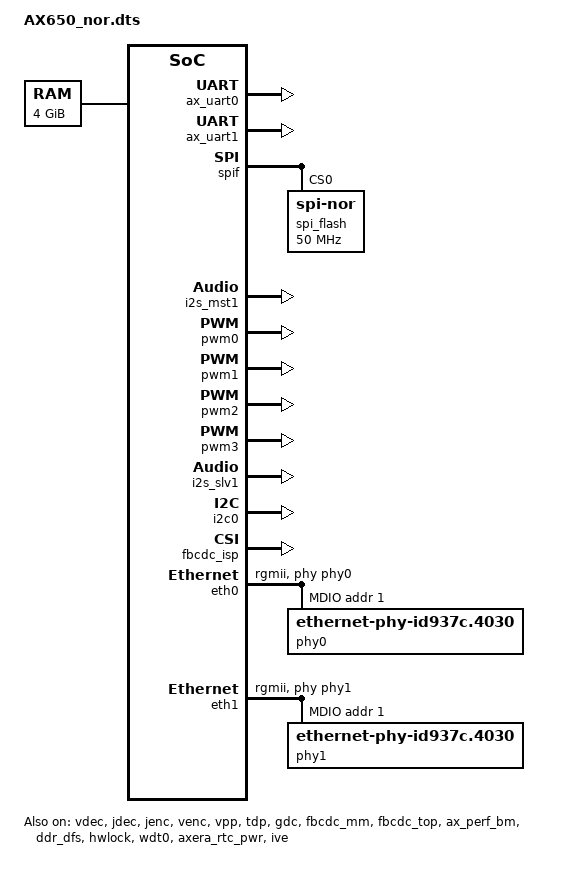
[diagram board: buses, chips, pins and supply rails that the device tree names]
// SPDX-License-Identifier: GPL-2.0
/*
 * dts file for Axera EVB Development Board
 *
 * Copyright (C) 2020, Axera Ltd.
 *
 */

/dts-v1/;
#include "AX650.dtsi"
#include "AX650_pinctrl.dtsi"
#include <dt-bindings/phy/jlsemi-dt-phy.h>
/ {
	memory@100000000 {
		device_type = "memory";
		reg = <0x1 0x00000000 0x1 0x00000000>;
	};
	reserved-memory {
		#address-cells = <2>;
		#size-cells = <2>;
		ranges;
		linux,cma {
			compatible = "shared-dma-pool";
			reusable;
			size = <0x00000000 0x2000000>;
			linux,cma-default;
		};
		axera_memory_dump@0 {
			compatible = "axera_memory_dump";
			reg = <0x1 0x050f0000 0x0 0x1000>;
			fix_addr = <0x7C8D6E02>;
		};
		ramoops_mem@106000000 {
			compatible = "ramoops";
			reg = <0x1 0x06000000 0x0 0xf0000>;
			record-size = <0x40000>;
			console-size = <0x80000>;
			ftrace-size = <0x20000>;
		};
	};

	chosen {
		bootargs = "Please DO NOT config this parameter. Please DO NOT config this parameter. Please DO NOT config this parameter. Please DO NOT config this parameter. Please DO NOT config this parameter. Please DO NOT config this parameter. Please DO NOT config this parameter. Please DO NOT config this parameter. Please config BOOTARGS_EMMC/BOOTARGS_SPINOR/BOOTARGS_SPI in u-boot-2020.04/include/configs/ax650_nor.h";
	};

	usb30: dwc3@0x30c00000 {
		compatible = "snps,dwc3";
		status = "okay";
	};

	usb31: dwc3@0x30d00000 {
		compatible = "snps,dwc3";
		status = "okay";
	};

	usb32: dwc3@0x28100000 {
		compatible = "snps,dwc3";
		status = "okay";
	};

	aliases {
		usb0 = &usb30;
		usb1 = &usb31;
		usb2 = &usb32;
	};

	fbcdc_config_val: fbcdc_config_val@0 {
		regs-num = <0x62>;
		regs-val = <0x00000020 0x00000001>,
			   <0x00000024 0x00000001>,
			   <0x00000000 0x00000000>,
			   <0x00000014 0x00000000>,
			   <0x00000048 0x0000001c>,
			   <0x0000024c 0x00000010>,
			   <0x0000004c 0x8000006b>,
			   <0x00000054 0x8000006b>,
			   <0x0000005c 0xc7b8a46b>,
			   <0x00000064 0xc7b8a46b>,
			   <0x0000006c 0x70000004>,
			   <0x00000074 0xc5040f71>,
			   <0x0000007c 0xc7148d60>,
			   <0x00000084 0x60000000>,
			   <0x0000008c 0x20000000>,
			   <0x00000094 0x50000000>,
			   <0x0000009c 0xc5a8207b>,
			   <0x000000a4 0x40000000>,
			   <0x000000ac 0xc7b8a46b>,
			   <0x000000b4 0x70000004>,
			   <0x000000bc 0xb0148d60>,
			   <0x000000c4 0x9000124a>,
			   <0x000000cc 0xb0148d60>,
			   <0x000000d4 0x9000124a>,
			   <0x000000dc 0xb0148d60>,
			   <0x000000e4 0x9000124a>,
			   <0x000000ec 0xb0148d60>,
			   <0x000000f4 0x9000124a>,
			   <0x000000fc 0xb0148d60>,
			   <0x00000104 0x9000124a>,
			   <0x0000010c 0xb0148d60>,
			   <0x00000114 0x9000124a>,
			   <0x0000011c 0xb0148d60>,
			   <0x00000124 0x9000124a>,
			   <0x0000012c 0x10000000>,
			   <0x00000050 0x0625a820>,
			   <0x00000058 0x0625a820>,
			   <0x00000060 0x0625a820>,
			   <0x00000068 0x0625a820>,
			   <0x00000070 0x0e65a820>,
			   <0x00000078 0x48d60c51>,
			   <0x00000080 0xc5181ccb>,
			   <0x00000088 0x10b5040f>,
			   <0x00000090 0x00000249>,
			   <0x00000098 0x01181cd3>,
			   <0x000000a0 0x8a46b062>,
			   <0x000000a8 0x0009c928>,
			   <0x000000b0 0x0628c0e6>,
			   <0x000000b8 0x9285a820>,
			   <0x000000c0 0xc5181cd3>,
			   <0x000000c8 0x16a081ee>,
			   <0x000000d0 0xc5181cd3>,
			   <0x000000d8 0x16a081ee>,
			   <0x000000e0 0xc5181cd3>,
			   <0x000000e8 0x16a081ee>,
			   <0x000000f0 0xc5181cd3>,
			   <0x000000f8 0x16a081ee>,
			   <0x00000100 0xc5181cd3>,
			   <0x00000108 0x16a081ee>,
			   <0x00000110 0xc5181cd3>,
			   <0x00000118 0x16a081ee>,
			   <0x00000120 0xc5181cd3>,
			   <0x00000128 0x16a081ee>,
			   <0x00000130 0x00000013>,
			   <0x00000250 0x40000000>,
			   <0x00000258 0x40000000>,
			   <0x00000260 0x60000000>,
			   <0x00000268 0x60000000>,
			   <0x00000270 0x80000029>,
			   <0x00000278 0x80000029>,
			   <0x00000280 0x30000000>,
			   <0x00000288 0x90000101>,
			   <0x00000290 0xa0002029>,
			   <0x00000298 0xa0002029>,
			   <0x000002a0 0xa0002029>,
			   <0x000002a8 0xa0002029>,
			   <0x000002b0 0xa0002029>,
			   <0x000002b8 0xa0002029>,
			   <0x000002c0 0xa0002029>,
			   <0x000002c8 0xa0002029>,
			   <0x000002d0 0x20000000>,
			   <0x00000254 0x00018820>,
			   <0x0000025c 0x00018820>,
			   <0x00000264 0x0a418820>,
			   <0x0000026c 0x0a418820>,
			   <0x00000274 0x06239820>,
			   <0x0000027c 0x06239820>,
			   <0x00000284 0x00002020>,
			   <0x0000028c 0x48311cc9>,
			   <0x00000294 0x06239928>,
			   <0x0000029c 0x06239928>,
			   <0x000002a4 0x06239928>,
			   <0x000002ac 0x06239928>,
			   <0x000002b4 0x06239928>,
			   <0x000002bc 0x06239928>,
			   <0x000002c4 0x06239928>,
			   <0x000002cc 0x06239928>,
			   <0x000002d4 0x00000128>;
	};

	fbcdc_config_val_top: fbcdc_config_val_top@0 {
		regs-num = <0x62>;
		regs-val = <0x00000020 0x00000001>,
			   <0x00000024 0x00000001>,
			   <0x00000000 0x00000001>, /* reverse fbc bypass enable signal of top module */
			   <0x00000014 0x00000001>, /* reverse fbdc bypass enable signal of top module */
			   <0x00000048 0x0000001c>,
			   <0x0000024c 0x00000010>,
			   <0x0000004c 0x8000006b>,
			   <0x00000054 0x8000006b>,
			   <0x0000005c 0xc7b8a46b>,
			   <0x00000064 0xc7b8a46b>,
			   <0x0000006c 0x70000004>,
			   <0x00000074 0xc5040f71>,
			   <0x0000007c 0xc7148d60>,
			   <0x00000084 0x60000000>,
			   <0x0000008c 0x20000000>,
			   <0x00000094 0x50000000>,
			   <0x0000009c 0xc5a8207b>,
			   <0x000000a4 0x40000000>,
			   <0x000000ac 0xc7b8a46b>,
			   <0x000000b4 0x70000004>,
			   <0x000000bc 0xb0148d60>,
			   <0x000000c4 0x9000124a>,
			   <0x000000cc 0xb0148d60>,
			   <0x000000d4 0x9000124a>,
			   <0x000000dc 0xb0148d60>,
			   <0x000000e4 0x9000124a>,
			   <0x000000ec 0xb0148d60>,
			   <0x000000f4 0x9000124a>,
			   <0x000000fc 0xb0148d60>,
			   <0x00000104 0x9000124a>,
			   <0x0000010c 0xb0148d60>,
			   <0x00000114 0x9000124a>,
			   <0x0000011c 0xb0148d60>,
			   <0x00000124 0x9000124a>,
			   <0x0000012c 0x10000000>,
			   <0x00000050 0x0625a820>,
			   <0x00000058 0x0625a820>,
			   <0x00000060 0x0625a820>,
			   <0x00000068 0x0625a820>,
			   <0x00000070 0x0e65a820>,
			   <0x00000078 0x48d60c51>,
			   <0x00000080 0xc5181ccb>,
			   <0x00000088 0x10b5040f>,
			   <0x00000090 0x00000249>,
			   <0x00000098 0x01181cd3>,
			   <0x000000a0 0x8a46b062>,
			   <0x000000a8 0x0009c928>,
			   <0x000000b0 0x0628c0e6>,
			   <0x000000b8 0x9285a820>,
			   <0x000000c0 0xc5181cd3>,
			   <0x000000c8 0x16a081ee>,
			   <0x000000d0 0xc5181cd3>,
			   <0x000000d8 0x16a081ee>,
			   <0x000000e0 0xc5181cd3>,
			   <0x000000e8 0x16a081ee>,
			   <0x000000f0 0xc5181cd3>,
			   <0x000000f8 0x16a081ee>,
			   <0x00000100 0xc5181cd3>,
			   <0x00000108 0x16a081ee>,
			   <0x00000110 0xc5181cd3>,
			   <0x00000118 0x16a081ee>,
			   <0x00000120 0xc5181cd3>,
			   <0x00000128 0x16a081ee>,
			   <0x00000130 0x00000013>,
			   <0x00000250 0x40000000>,
			   <0x00000258 0x40000000>,
			   <0x00000260 0x60000000>,
			   <0x00000268 0x60000000>,
			   <0x00000270 0x80000029>,
			   <0x00000278 0x80000029>,
			   <0x00000280 0x30000000>,
			   <0x00000288 0x90000101>,
			   <0x00000290 0xa0002029>,
			   <0x00000298 0xa0002029>,
			   <0x000002a0 0xa0002029>,
			   <0x000002a8 0xa0002029>,
			   <0x000002b0 0xa0002029>,
			   <0x000002b8 0xa0002029>,
			   <0x000002c0 0xa0002029>,
			   <0x000002c8 0xa0002029>,
			   <0x000002d0 0x20000000>,
			   <0x00000254 0x00018820>,
			   <0x0000025c 0x00018820>,
			   <0x00000264 0x0a418820>,
			   <0x0000026c 0x0a418820>,
			   <0x00000274 0x06239820>,
			   <0x0000027c 0x06239820>,
			   <0x00000284 0x00002020>,
			   <0x0000028c 0x48311cc9>,
			   <0x00000294 0x06239928>,
			   <0x0000029c 0x06239928>,
			   <0x000002a4 0x06239928>,
			   <0x000002ac 0x06239928>,
			   <0x000002b4 0x06239928>,
			   <0x000002bc 0x06239928>,
			   <0x000002c4 0x06239928>,
			   <0x000002cc 0x06239928>,
			   <0x000002d4 0x00000128>;
	};

	aliases {
		pcie0 = &pcie0_rc;
		pcie1 = &pcie1_ep;

		ethernet0 = &eth0;
		ethernet1 = &eth1;
	};

	vfb0: vfb@0 {
		status = "disabled";
		compatible = "axera,vfb";
		id = <0>;
		width = <1920>;
		height = <1080>;
		bpp = <32>;
		buf-num = <2>;
	};

	vfb1: vfb@1 {
		status = "disabled";
		compatible = "axera,vfb";
		id = <1>;
		width = <1920>;
		height = <1080>;
		bpp = <32>;
		buf-num = <2>;
	};

	vfb2: vfb@2 {
		status = "disabled";
		compatible = "axera,vfb";
		id = <2>;
		width = <1920>;
		height = <1080>;
		bpp = <32>;
		buf-num = <2>;
	};

	vfb3: vfb@3 {
		status = "disabled";
		compatible = "axera,vfb";
		id = <3>;
		width = <64>;
		height = <64>;
		bpp = <32>;
		buf-num = <2>;
		cursor;
	};
	axera_logctl {
		compatible = "axera,logctl";
		config = "/etc/ax_syslog.conf";
		logstate = /bits/ 8 <1 1>;
		loglevel = /bits/ 8 <4 4>;
	};

};

&emmc {
	status = "disabled";
	sdhci-caps-mask = <0x2 0x03200000>;
	//sdhci-caps = <0x01000000>;//SDHCI_CAN_VDD_330
	bus-width = <8>;
	max-frequency = <200000000>;
	cap-mmc-hw-reset;
	cap-mmc-highspeed;
	mmc-hs200-1_8v;
	mmc-hs400-1_8v;
	mmc-hs400-enhanced-strobe;
	no-1-8-v;
	no-sdio;
	no-sd;
	non-removable;
	disable-wp;
	axera,phy-cnfg = <0x00CC0000>;
	axera,phy-cmdpad-cnfg = <0x0449>;
	axera,phy-datapad-cnfg = <0x0449>;
	axera,phy-clkpad-cnfg = <0x0440>;
	axera,phy-stbpad-cnfg = <0x0451>;
	axera,phy-rstnpad-cnfg = <0x0449>;
	axera,phy-commdl-cnfg = <0x0>;
	axera,phy-sdclkdl-cnfg = <0x0>;
	axera,phy-sdclkdl-dc = <0x7F>;
	axera,phy-smpldl-cnfg = <0xC>;
	axera,phy-atdl-cnfg = <0xC>;
};

&sd {
	status = "disabled";
	sdhci-caps-mask = <0x7 0x00200000>;
	bus-width = <4>;
	max-frequency = <200000000>;
	cap-sd-highspeed;
	sd-uhs-sdr25;
	sd-uhs-sdr12;
	sd-uhs-sdr50;
	sd-uhs-sdr104;
	no-1-8-v;
	no-sdio;
	no-mmc;
	disable-wp;
	axera,swt1v8-drv-str = <0xCC>;
	axera,phy-cnfg = <0x00CD0000>;
	axera,phy-cmdpad-cnfg = <0x044A>;
	axera,phy-datapad-cnfg = <0x044A>;
	axera,phy-clkpad-cnfg = <0x0440>;
	axera,phy-stbpad-cnfg = <0x0452>;
	axera,phy-rstnpad-cnfg = <0x0440>;
	axera,phy-commdl-cnfg = <0x0>;
	axera,phy-sdclkdl-cnfg = <0x0>;
	axera,phy-sdclkdl-dc = <0x7F>;
	axera,phy-smpldl-cnfg = <0xC>;
	axera,phy-atdl-cnfg = <0xC>;
};

&sdio {
	status = "disabled";
	sdhci-caps-mask = <0x7 0x00200000>;
	bus-width = <4>;
	max-frequency = <200000000>;
	cap-mmc-hw-reset;
	cap-sd-highspeed;
	sd-uhs-sdr25;
	sd-uhs-sdr12;
	sd-uhs-sdr50;
	sd-uhs-sdr104;
	no-1-8-v;
	no-sd;
	no-mmc;
	disable-wp;
	axera,swt1v8-drv-str = <0xCC>;
	axera,phy-cnfg = <0x00CD0000>;
	axera,phy-cmdpad-cnfg = <0x044A>;
	axera,phy-datapad-cnfg = <0x044A>;
	axera,phy-clkpad-cnfg = <0x0440>;
	axera,phy-stbpad-cnfg = <0x0452>;
	axera,phy-rstnpad-cnfg = <0x0440>;
	axera,phy-commdl-cnfg = <0x0>;
	axera,phy-sdclkdl-cnfg = <0x0>;
	axera,phy-sdclkdl-dc = <0x7F>;
	axera,phy-smpldl-cnfg = <0xC>;
	axera,phy-atdl-cnfg = <0xC>;
};

&ax_uart0 {
	status = "okay";
};

&ax_uart1 {
	dmas = <&dmac 42 &dmac 43>;
	dma-names = "tx", "rx";
	status = "okay";
};

&pcie0_rc {
    status = "disabled";
};

&pcie0_ep {
    status = "disabled";
};

&pcie1_rc {
    status = "disabled";
};

&pcie1_ep {
    status = "disabled";
};


&spif {
	status = "okay";
	/*spi_nand@0 {
		compatible = "spi-nand";
		reg = <0>;
		spi-max-frequency = <1000000>;
	};*/
	spi_flash@0 {
		#address-cells = <1>;
		#size-cells = <1>;
		compatible = "jedec,spi-nor";
		reg = <0>;
		spi-max-frequency = <50000000>;
	};
};

&i2s_mst1 {
       status = "okay";
};

&pwm0 {
	status = "okay";
};

&pwm1 {
	status = "okay";
};

&pwm2 {
	status = "okay";
};

&pwm3 {
	status = "okay";
};

&i2s_slv1 {
	status = "okay";
};

&i2c0 {
	status = "okay";
	scl-gpio = <&port4a 19 0>;
	sda-gpio = <&port4a 20 0>;
	pinctrl-names = "default", "gpio";
	pinctrl-0 = <&i2c0_scl_m_pins>, <&i2c0_sda_m_pins>;
	pinctrl-1 = <&gpio4_a19_pins>, <&gpio4_a20_pins>;
};

&i2c5 {
	status = "disabled";
	clock-frequency = <100000>;
	#address-cells = <0x1>;
	#size-cells = <0x0>;
	scl-gpio = <&port1a 26 0>;
	sda-gpio = <&port1a 27 0>;
	pinctrl-names = "default", "gpio";
	pinctrl-0 = <&i2c5_scl_pins>, <&i2c5_sda_pins>;
	pinctrl-1 = <&gpio1_a26_pins>, <&gpio1_a27_pins>;

	m31-dphy@68 {
		compatible = "m31,dphy";
		reg = <0x68>;
	};
};

&drm0 {
	status = "disabled";
};

&vo0 {
	status = "disabled";
};

&vo1 {
	status = "disabled";
};

&crtc0 {
	status = "disabled";
};

&crtc1 {
	status = "disabled";
};

&hdmi0 {
	status = "disabled";
};

&hdmi1 {
	status = "disabled";
};

&dsi {
	status = "disabled";
};

&vdec {
	status = "okay";
};

&jdec {
	status = "okay";
};

&jenc {
	status = "okay";
};

&venc {
	status = "okay";
};

&vpp {
	status = "okay";
};

&tdp {
	status = "okay";
};

&gdc {
	status = "okay";
};

&fbcdc_isp {
	regs-param = <&fbcdc_config_val>;
	status = "okay";
};

&fbcdc_mm {
	regs-param = <&fbcdc_config_val>;
	status = "okay";
};

&fbcdc_top {
	regs-param = <&fbcdc_config_val_top>;
	status = "okay";
};

&panel_dsi {
	status = "disabled";
	prepare-delay-ms = <0>;
	unprepare-delay-ms = <0>;
	enable-delay-ms = <0>;
	disable-delay-ms = <0>;
	reset-low-delay-ms = <0>;
	reset-high-delay-ms = <0>;
	dsi,format = <MIPI_DSI_FMT_RGB565>;
	dsi,lanes = <4>;
	dsi,flags = <(MIPI_DSI_MODE_VIDEO_SYNC_PULSE | MIPI_DSI_MODE_VIDEO)>;
	panel-init-seq = [39 00 04 ff 98 81 03
			  15 00 02 01 00 15 00 02 02 00 15 00 02 03 73
			  15 00 02 04 d3 15 00 02 05 00 15 00 02 06 0a
			  15 00 02 07 0e 15 00 02 08 00 15 00 02 09 01
			  15 00 02 0a 01 15 00 02 0b 01 15 00 02 0c 00
			  15 00 02 0d 01 15 00 02 0e 01 15 00 02 0f 01
			  15 00 02 10 01 15 00 02 11 00 15 00 02 12 00
			  15 00 02 13 00 15 00 02 14 00 15 00 02 15 00
			  15 00 02 16 00 15 00 02 17 00 15 00 02 18 00
			  15 00 02 19 00 15 00 02 1a 00 15 00 02 1b 00
			  15 00 02 1c 00 15 00 02 1d 00 15 00 02 1e 40
			  15 00 02 1f 80 15 00 02 20 06 15 00 02 21 01
			  15 00 02 22 00 15 00 02 23 00 15 00 02 24 00
			  15 00 02 25 00 15 00 02 26 00 15 00 02 27 00
			  15 00 02 28 33 15 00 02 29 03 15 00 02 2a 00
			  15 00 02 2b 00 15 00 02 2c 00 15 00 02 2d 00
			  15 00 02 2e 00 15 00 02 2f 00 15 00 02 30 00
			  15 00 02 31 00 15 00 02 32 00 15 00 02 33 00
			  15 00 02 34 03 15 00 02 35 00 15 00 02 36 03
			  15 00 02 37 00 15 00 02 38 00 15 00 02 39 00
			  15 00 02 3a 40 15 00 02 3b 40 15 00 02 3c 00
			  15 00 02 3d 00 15 00 02 3e 00 15 00 02 3f 00
			  15 00 02 40 00 15 00 02 41 00 15 00 02 42 00
			  15 00 02 43 00 15 00 02 44 00 15 00 02 50 01
			  15 00 02 51 23 15 00 02 52 45 15 00 02 53 67
			  15 00 02 54 89 15 00 02 55 ab 15 00 02 56 01
			  15 00 02 57 23 15 00 02 58 45 15 00 02 59 67
			  15 00 02 5a 89 15 00 02 5b ab 15 00 02 5c cd
			  15 00 02 5d ef 15 00 02 5e 11 15 00 02 5f 08
			  15 00 02 60 02 15 00 02 61 00 15 00 02 62 01
			  15 00 02 63 0d 15 00 02 64 0c 15 00 02 65 02
			  15 00 02 66 02 15 00 02 67 02 15 00 02 68 02
			  15 00 02 69 02 15 00 02 6a 02 15 00 02 6b 0f
			  15 00 02 6c 02 15 00 02 6d 02 15 00 02 6e 02
			  15 00 02 6f 02 15 00 02 70 02 15 00 02 71 02
			  15 00 02 72 0e 15 00 02 73 06 15 00 02 74 07
			  15 00 02 75 08 15 00 02 76 02 15 00 02 77 00
			  15 00 02 78 01 15 00 02 79 0d 15 00 02 7a 0c
			  15 00 02 7b 02 15 00 02 7c 02 15 00 02 7d 02
			  15 00 02 7e 02 15 00 02 7f 02 15 00 02 80 02
			  15 00 02 81 0f 15 00 02 82 02 15 00 02 83 02
			  15 00 02 84 02 15 00 02 85 02 15 00 02 86 02
			  15 00 02 87 02 15 00 02 88 0e 15 00 02 89 06
			  15 00 02 8a 07
			  39 00 04 ff 98 81 04
			  15 00 02 6c 15 15 00 02 6e 1a 15 00 02 6f 33
			  15 00 02 8d 15 15 00 02 3a a4 15 00 02 87 2a
			  15 00 02 63 c0 15 00 02 26 76 15 00 02 b2 d1
			  39 00 04 ff 98 81 01
			  15 00 02 22 08 15 00 02 31 00 15 00 02 50 9e
			  15 00 02 51 9e 15 00 02 60 14 15 00 02 a0 00
			  15 00 02 a1 1b 15 00 02 a2 2b 15 00 02 a3 15
			  15 00 02 a4 19 15 00 02 a5 2c 15 00 02 a6 20
			  15 00 02 a7 1d 15 00 02 a8 98 15 00 02 a9 1d
			  15 00 02 aa 29 15 00 02 ab 8a 15 00 02 ac 1d
			  15 00 02 ad 1c 15 00 02 ae 50 15 00 02 af 24
			  15 00 02 b0 2c 15 00 02 b1 52 15 00 02 b2 60
			  15 00 02 b3 2a 15 00 02 c0 00 15 00 02 c1 1b
			  15 00 02 c2 2c 15 00 02 c3 16 15 00 02 c4 18
			  15 00 02 c5 2c 15 00 02 c6 20 15 00 02 c7 23
			  15 00 02 c8 98 15 00 02 c9 1d 15 00 02 ca 2a
			  15 00 02 cb 8a 15 00 02 cc 1e 15 00 02 cd 1d
			  15 00 02 ce 50 15 00 02 cf 24 15 00 02 d0 2c
			  15 00 02 d1 52 15 00 02 d2 60 15 00 02 d3 2a
			  39 00 04 ff 98 81 00
			  15 00 02 36 02 15 00 02 53 24 15 00 02 55 01
			  15 00 02 80 04
			  39 00 03 51 ff 0f
			  15 00 02 3a 05
			  05 78 01 11];
	panel-exit-seq = [05 00 01 28];

	display-timings {

		timing0 {
			/* 720x1280@20 */
			clock-frequency = <25000000>;
			hactive = <720>;
			vactive = <1280>;
			hfront-porch = <80>;
			hsync-len = <10>;
			hback-porch = <150>;
			vfront-porch = <20>;
			vsync-len = <10>;
			vback-porch = <20>;
			hsync-active = <0>;
			vsync-active = <0>;
			de-active = <0>;
		};
	};
};

&panel0 {
	status = "disabled";

	display-timings {

		timing0: timing {
			/* 720x480@60 */
			clock-frequency = <27000000>;
			hactive = <720>;
			vactive = <480>;
			hfront-porch = <16>;
			hsync-len = <62>;
			hback-porch = <60>;
			vfront-porch = <19>;
			vsync-len = <6>;
			vback-porch = <30>;
			hsync-active = <1>;
			vsync-active = <1>;
			de-active = <1>;
		};
	};
};

&ax_perf_bm {
       status = "okay";
};

&ddr_dfs {
       status = "okay";
};

&hwlock {
       status = "okay";
};

&eth0 {
	status = "okay";

	phy-handle = <&phy0>;
	phy-mode = "rgmii";

	mdio {
		#address-cells = <1>;
		#size-cells = <0>;
		compatible = "snps,dwmac-mdio";
		phy0: jl2xxx-phy@1 {
			compatible = "ethernet-phy-id937c.4030";
			jl2xxx,led-enable = <JL2XXX_LED_CTRL_EN>;
			jl2xxx,led-mode = <JL2XXX_CFG_LED_MODE>;
			jl2xxx,led-period = <JL2XXX_GLOBAL_PERIOD_MS>;
			jl2xxx,led-on = <JL2XXX_GLOBAL_ON_MS>;
			jl2xxx,led-polarity = <JL2XXX_LED_POLARITY>;
			jl2xxx,patch-enable = <JL2XXX_PATCH_CTRL_EN>;
			jl2xxx,rgmii-enable = <JL2XXX_RGMII_CTRL_EN>;
			jl2xxx,rgmii-tx-delay = <JL2XXX_RGMII_TX_DLY_2NS>;
			jl2xxx,rgmii-rx-delay = <JL2XXX_RGMII_RX_DLY_2NS>;
			jl2xxx,clk-enable = <JL2XXX_CLK_CTRL_EN>;
			jl2xxx,fld-enable = <JL2XXX_FLD_CTRL_EN>;
			jl2xxx,fld-delay = <JL2XXX_FLD_DELAY>;
			jl2xxx,wol-enable = <JL2XXX_WOL_CTRL_EN>;
			jl2xxx,interrupt-enable = <JL2XXX_INTR_CTRL_EN>;
			jl2xxx,downshift-enable = <JL2XXX_DSFT_CTRL_EN>;
			jl2xxx,downshift-count = <JL2XXX_DSFT_AN_CNT>;
			jl2xxx,work_mode-enable = <JL2XXX_WORK_MODE_CTRL_EN>;
			jl2xxx,work_mode-mode = <JL2XXX_WOEK_MODE_MODE>;
			jl2xxx,lpbk-enable = <JL2XXX_LPBK_CTRL_EN>;
			jl2xxx,lpbk-mode = <JL2XXX_LPBK_MODE>;
			jl2xxx,slew_rate-enable = <JL2XXX_SLEW_RATE_CTRL_EN>;
			jl2xxx,rxc_out-enable = <JL2XXX_RXC_OUT_CTRL_EN>;
			reg = <1>;
		};
	};
};

&eth1 {
	status = "okay";

	phy-handle = <&phy1>;
	phy-mode = "rgmii";

	mdio {
		#address-cells = <1>;
		#size-cells = <0>;
		compatible = "snps,dwmac-mdio";
		phy1: jl2xxx-phy@1 {
			compatible = "ethernet-phy-id937c.4030";
			jl2xxx,led-enable = <JL2XXX_LED_CTRL_EN>;
			jl2xxx,led-mode = <JL2XXX_CFG_LED_MODE>;
			jl2xxx,led-period = <JL2XXX_GLOBAL_PERIOD_MS>;
			jl2xxx,led-on = <JL2XXX_GLOBAL_ON_MS>;
			jl2xxx,led-polarity = <JL2XXX_LED_POLARITY>;
			jl2xxx,patch-enable = <JL2XXX_PATCH_CTRL_EN>;
			jl2xxx,rgmii-enable = <JL2XXX_RGMII_CTRL_EN>;
			jl2xxx,rgmii-tx-delay = <JL2XXX_RGMII_TX_DLY_2NS>;
			jl2xxx,rgmii-rx-delay = <JL2XXX_RGMII_RX_DLY_2NS>;
			jl2xxx,clk-enable = <JL2XXX_CLK_CTRL_EN>;
			jl2xxx,fld-enable = <JL2XXX_FLD_CTRL_EN>;
			jl2xxx,fld-delay = <JL2XXX_FLD_DELAY>;
			jl2xxx,wol-enable = <JL2XXX_WOL_CTRL_EN>;
			jl2xxx,interrupt-enable = <JL2XXX_INTR_CTRL_EN>;
			jl2xxx,downshift-enable = <JL2XXX_DSFT_CTRL_EN>;
			jl2xxx,downshift-count = <JL2XXX_DSFT_AN_CNT>;
			jl2xxx,work_mode-enable = <JL2XXX_WORK_MODE_CTRL_EN>;
			jl2xxx,work_mode-mode = <JL2XXX_WOEK_MODE_MODE>;
			jl2xxx,lpbk-enable = <JL2XXX_LPBK_CTRL_EN>;
			jl2xxx,lpbk-mode = <JL2XXX_LPBK_MODE>;
			jl2xxx,slew_rate-enable = <JL2XXX_SLEW_RATE_CTRL_EN>;
			jl2xxx,rxc_out-enable = <JL2XXX_RXC_OUT_CTRL_EN>;
			reg = <1>;
		};
	};
};

&dmac {
	status = "okay";
};

&dmaxor {
	status = "okay";
};

&dmadim {
	status = "okay";
};

&wdt0 {
	status = "okay";
};

&axera_rtc_pwr {
        status = "okay";
};

&ive {
	status = "okay";
};
